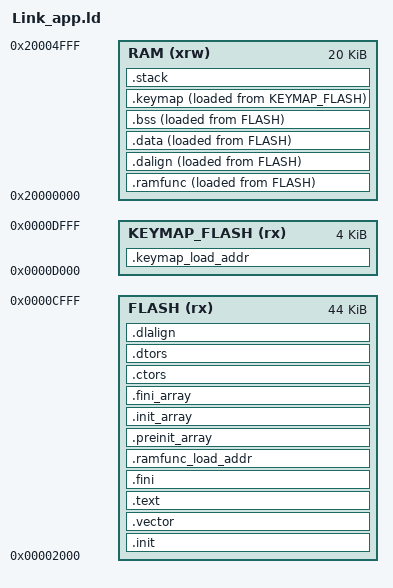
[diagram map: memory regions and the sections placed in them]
ENTRY( _start )

__stack_size = 2048;

PROVIDE( _stack_size = __stack_size );
PROVIDE(APP_ENTRY_ADDR = ORIGIN(FLASH));


MEMORY
{  
  FLASH (rx) : ORIGIN = 0x0 + 8K, LENGTH = 44K
  KEYMAP_FLASH (rx) : ORIGIN = ORIGIN(FLASH) + LENGTH(FLASH), LENGTH = 4K
  RAM (xrw) : ORIGIN = 0x20000000, LENGTH = 20K
}


SECTIONS
{

    .init :
    {
        _sinit = .;
        . = ALIGN(4);
        KEEP(*(SORT_NONE(.init)))
        . = ALIGN(4);
        _einit = .;
    } >FLASH AT>FLASH

  .vector :
  {
      *(.vector);
      . = ALIGN(64);
  } >FLASH AT>FLASH

    .text :
    {
        . = ALIGN(4);
        *(.text)
        *(.text.*)
        *(.rodata)
        *(.rodata*)
        *(.gnu.linkonce.t.*)
        . = ALIGN(4);
    } >FLASH AT>FLASH 

    .fini :
    {
        KEEP(*(SORT_NONE(.fini)))
        . = ALIGN(4);
    } >FLASH AT>FLASH

    PROVIDE( _etext = . );
    PROVIDE( _eitcm = . );

    .ramfunc_load_addr :
    {
        . = ALIGN(4);
        PROVIDE(_ramfunc_lma = .);
    } >FLASH AT>FLASH

    .ramfunc :
    {
        . = ALIGN(4);
        PROVIDE(_ramfunc_vma = .);
        *(.ramfunc)
        *(.ramfunc.*)
        . = ALIGN(4);
        PROVIDE(_eramfunc = .);
    } >RAM AT>FLASH

    .preinit_array  :
    {
      PROVIDE_HIDDEN (__preinit_array_start = .);
      KEEP (*(.preinit_array))
      PROVIDE_HIDDEN (__preinit_array_end = .);
    } >FLASH AT>FLASH 
    
    .init_array     :
    {
      PROVIDE_HIDDEN (__init_array_start = .);
      KEEP (*(SORT_BY_INIT_PRIORITY(.init_array.*) SORT_BY_INIT_PRIORITY(.ctors.*)))
      KEEP (*(.init_array EXCLUDE_FILE (*crtbegin.o *crtbegin?.o *crtend.o *crtend?.o ) .ctors))
      PROVIDE_HIDDEN (__init_array_end = .);
    } >FLASH AT>FLASH 
    
    .fini_array     :
    {
      PROVIDE_HIDDEN (__fini_array_start = .);
      KEEP (*(SORT_BY_INIT_PRIORITY(.fini_array.*) SORT_BY_INIT_PRIORITY(.dtors.*)))
      KEEP (*(.fini_array EXCLUDE_FILE (*crtbegin.o *crtbegin?.o *crtend.o *crtend?.o ) .dtors))
      PROVIDE_HIDDEN (__fini_array_end = .);
    } >FLASH AT>FLASH 

    .ctors          :
    {
      KEEP (*crtbegin.o(.ctors))
      KEEP (*crtbegin?.o(.ctors))
      KEEP (*(EXCLUDE_FILE (*crtend.o *crtend?.o ) .ctors))
      KEEP (*(SORT(.ctors.*)))
      KEEP (*(.ctors))
    } >FLASH AT>FLASH 
    
    .dtors          :
    {
      KEEP (*crtbegin.o(.dtors))
      KEEP (*crtbegin?.o(.dtors))
      KEEP (*(EXCLUDE_FILE (*crtend.o *crtend?.o ) .dtors))
      KEEP (*(SORT(.dtors.*)))
      KEEP (*(.dtors))
    } >FLASH AT>FLASH 

    .dalign :
    {
        . = ALIGN(4);
        PROVIDE(_data_vma = .);
    } >RAM AT>FLASH    

    .dlalign :
    {
        . = ALIGN(4); 
        PROVIDE(_data_lma = .);
    } >FLASH AT>FLASH

    .data :
    {
        *(.gnu.linkonce.r.*)
        *(.data .data.*)
        *(.gnu.linkonce.d.*)
        . = ALIGN(8);
        PROVIDE( __global_pointer$ = . + 0x800 );
        *(.sdata .sdata.*)
        *(.sdata2.*)
        *(.gnu.linkonce.s.*)
        . = ALIGN(8);
        *(.srodata.cst16)
        *(.srodata.cst8)
        *(.srodata.cst4)
        *(.srodata.cst2)
        *(.srodata .srodata.*)
        . = ALIGN(4);
        PROVIDE( _edata = .);
    } >RAM AT>FLASH

    .bss :
    {
        . = ALIGN(4);
        PROVIDE( _sbss = .);
        *(.sbss*)
        *(.gnu.linkonce.sb.*)
        *(.bss*)
        *(.gnu.linkonce.b.*)        
        *(COMMON*)
        . = ALIGN(4);
        PROVIDE( _ebss = .);
    } >RAM AT>FLASH


        /* Keymap: place in RAM at runtime, load image from KEYMAP_FLASH */
        .keymap_load_addr :
        {
            . = ALIGN(4);
            PROVIDE(_keymap_lma = .);
        } >KEYMAP_FLASH

        .keymap :
        {
            . = ALIGN(4);
            PROVIDE(_keymap_vma = .);
            KEEP(*(.keymap))
            . = ALIGN(4);
            PROVIDE(_keymap_end = .);
        } >RAM AT>KEYMAP_FLASH

        PROVIDE( _end = _ebss);
        PROVIDE( end = . );

    .stack ORIGIN(RAM) + LENGTH(RAM) - __stack_size :
    {
        PROVIDE( _heap_end = . );   
        . = ALIGN(4);
        PROVIDE(_susrstack = . );
        . = . + __stack_size;
        PROVIDE( _eusrstack = .);
    } >RAM 

}
